# USB_USB2SS_PHY2_0F908000h register map
Vendor: Texas Instruments
Registers are 32-bit, read-write, reset 0x0 unless marked. A register's access mark holds for its fields unless they carry their own. Offsets are as the file gives them; [hi:lo] are bit positions; {n}, {i} and the like mark numbered series.

## usb2ss_phy2 (part 2 of 3)
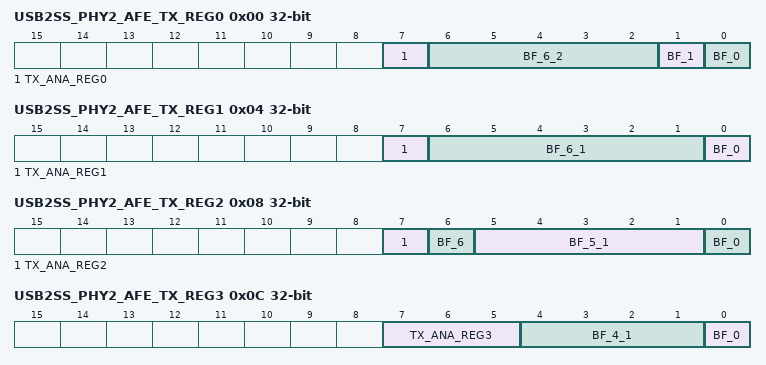
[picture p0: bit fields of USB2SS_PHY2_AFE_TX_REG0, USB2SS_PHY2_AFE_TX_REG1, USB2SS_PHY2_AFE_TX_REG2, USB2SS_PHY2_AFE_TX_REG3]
0x00 USB2SS_PHY2_AFE_TX_REG0 — This is a reserved register or field. It should not be written or read, and the value should be ignored.
  [7] TX_ANA_REG0 — This is a reserved register or field. It should not be written or read, and the value should be ignored. Reset Source: usb2_sync_preset_n
  [6:2] BF_6_2 — This is a reserved register or field. It should not be written or read, and the value should be ignored. Reset Source: usb2_sync_preset_n
  [1] BF_1 — This is a reserved register or field. It should not be written or read, and the value should be ignored. Reset Source: usb2_sync_preset_n
  [0] BF_0 — This is a reserved register or field. It should not be written or read, and the value should be ignored. Reset Source: usb2_sync_preset_n
0x04 USB2SS_PHY2_AFE_TX_REG1 — HS TX trimming
  [7] TX_ANA_REG1 — 0 SCALE1 VALUE IS 0, 1 SCALE1 VALUE IS 0.5 Reset Source: usb2_sync_preset_n
  [6:1] BF_6_1 — 000000 BOOST CODE VALUE IS 0, 000001 BOOST CODE VALUE IS 1, 000010 BOOST CODE VALUE IS 2, 00011 BOOST CODE VALUE IS 3, 000100 BOOST CODE VALUE IS 4, 000101 BOOST CODE VALUE IS 5, 000110 BOOST CODE VALUE IS 6, 000111 BOOST CODE VALUE IS 7, 001000 BOOST CODE VALUE IS 8, 001001 BOOST CODE VALUE IS 9, 001010 BOOST CODE VALUE IS 10, 001011 BOOST CODE VALUE IS 11, 001100 BOOST CODE VALUE IS 12, 001101 BOOST CODE VALUE IS 13, 001110 BOOST CODE VALUE IS 14, 001111 BOOST CODE VALUE IS 15, 010000 BOOST CODE VALUE IS 16, 010001 BOOST CODE VALUE IS 17, 010010 BOOST CODE VALUE IS 18, 010011 BOOST CODE VALUE IS 19, 010100 BOOST CODE VALUE IS 20, 010101 BOOST CODE VALUE IS 21, 010110 BOOST CODE VALUE IS 22, 010111 BOOST CODE VALUE IS 23, 011000 BOOST CODE VALUE IS 24, 011001 BOOST CODE VALUE IS 24, 011010 BOOST CODE VALUE IS 26, 011011 BOOST CODE VALUE IS 27, 011100 BOOST CODE VALUE IS 28, 011101 BOOST CODE VALUE IS 29, 011110 BOOST CODE VALUE IS 30, 011111 BOOST CODE VALUE IS 31, 100000 BOOST CODE VALUE IS 16, 100001 BOOST CODE VALUE IS 17, 100010 BOOST CODE VALUE IS 18, 100011 BOOST CODE VALUE IS 19, 100100 BOOST CODE VALUE IS 20, 100101 BOOST CODE VALUE IS 21, 100110 BOOST CODE VALUE IS 22, 100111 BOOST CODE VALUE IS 23, 101000 BOOST CODE VALUE IS 24 , 101001 BOOST CODE VALUE IS 24, 101010 BOOST CODE VALUE IS 26, 101011 BOOST CODE VALUE IS 27, 101100 BOOST CODE VALUE IS 28, 101101 BOOST CODE VALUE IS 29, 101110 BOOST CODE VALUE IS 30, 101111 BOOST CODE VALUE IS 31, 110000 BOOST CODE VALUE IS 32, 110001 BOOST CODE VALUE IS 33, 110010 BOOST CODE VALUE IS 34, 110011 BOOST CODE VALUE IS 35, 110100 BOOST CODE VALUE IS 36, 110101 BOOST CODE VALUE IS 37, 110110 BOOST CODE VALUE IS 38, 110111 BOOST CODE VALUE IS 39, 111000 BOOST CODE VALUE IS 40, 111001 BOOST CODE VALUE IS 41, 111010 BOOST CODE VALUE IS 42, 111011 BOOST CODE VALUE IS 43, 111100 BOOST CODE VALUE IS 44, 111101 BOOST CODE VALUE IS 45, 111110 BOOST CODE VALUE IS 46, 111111 BOOST CODE VALUE IS 47. Reset Source: usb2_sync_preset_n
  [0] BF_0 — 0 Default BOOST CODE = 8, 1 BOOST CODE can be controlled by BITS [6:1]. Reset Source: usb2_sync_preset_n
0x08 USB2SS_PHY2_AFE_TX_REG2 — HS TX trimming
  [7] TX_ANA_REG2 — This is a reserved register or field. It should not be written or read, and the value should be ignored. Reset Source: usb2_sync_preset_n
  [6] BF_6 — This is a reserved register or field. It should not be written or read, and the value should be ignored. Reset Source: usb2_sync_preset_n
  [5:1] BF_5_1 — 00000 DEEMP CODE VALUE IS 0, 00001 DEEMP CODE VALUE IS 1, 00010 DEEMP CODE VALUE IS 2, 00011 DEEMP CODE VALUE IS 3, 00100 DEEMP CODE VALUE IS 4, 00101 DEEMP CODE VALUE IS 5, 00110 DEEMP CODE VALUE IS 6, 00111 DEEMP CODE VALUE IS 7, 01000 DEEMP CODE VALUE IS 8, 01001 DEEMP CODE VALUE IS 9, 01010 DEEMP CODE VALUE IS 10, 01011 DEEMP CODE VALUE IS 11, 01100 DEEMP CODE VALUE IS 12, 01101 DEEMP CODE VALUE IS 13, 01110 DEEMP CODE VALUE IS 14, 01111 DEEMP CODE VALUE IS 15, 10000 DEEMP CODE VALUE IS 8, 10001 DEEMP CODE VALUE IS 9, 10010 DEEMP CODE VALUE IS 10, 10011 DEEMP CODE VALUE IS 11, 10100 DEEMP CODE VALUE IS 12, 10101 DEEMP CODE VALUE IS 13, 10110 DEEMP CODE VALUE IS 14, 10111 DEEMP CODE VALUE IS 15, 11000 DEEMP CODE VALUE IS 16, 11001 DEEMP CODE VALUE IS 17, 11010 DEEMP CODE VALUE IS 18, 11011 DEEMP CODE VALUE IS 19, 11100 DEEMP CODE VALUE IS 20, 11101 DEEMP CODE VALUE IS 21, 11110 DEEMP CODE VALUE IS 22, 11111 DEEMP CODE VALUE IS 23. Reset Source: usb2_sync_preset_n
  [0] BF_0 — 0 Default DEEMP CODE = 8, 1 DEEMP CODE can be controlled by BITS 5:1. Reset Source: usb2_sync_preset_n
0x0C USB2SS_PHY2_AFE_TX_REG3 — This is a reserved register or field. It should not be written or read, and the value should be ignored.
  [7:5] TX_ANA_REG3 — This is a reserved register or field. It should not be written or read, and the value should be ignored. Reset Source: usb2_sync_preset_n
  [4:1] BF_4_1 — This is a reserved register or field. It should not be written or read, and the value should be ignored. Reset Source: usb2_sync_preset_n
  [0] BF_0 — This is a reserved register or field. It should not be written or read, and the value should be ignored. Reset Source: usb2_sync_preset_n
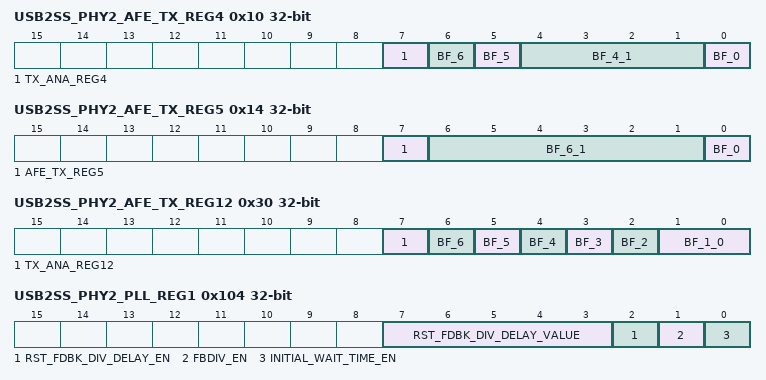
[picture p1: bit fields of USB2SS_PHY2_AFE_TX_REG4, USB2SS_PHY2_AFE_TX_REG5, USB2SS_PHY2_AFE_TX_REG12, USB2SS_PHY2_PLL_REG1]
0x10 USB2SS_PHY2_AFE_TX_REG4 — This is a reserved register or field. It should not be written or read, and the value should be ignored.
  [7] TX_ANA_REG4 — This is a reserved register or field. It should not be written or read, and the value should be ignored. Reset Source: usb2_sync_preset_n
  [6] BF_6 — This is a reserved register or field. It should not be written or read, and the value should be ignored. Reset Source: usb2_sync_preset_n
  [5] BF_5 — This is a reserved register or field. It should not be written or read, and the value should be ignored. Reset Source: usb2_sync_preset_n
  [4:1] BF_4_1 — This is a reserved register or field. It should not be written or read, and the value should be ignored. Reset Source: usb2_sync_preset_n
  [0] BF_0 — This is a reserved register or field. It should not be written or read, and the value should be ignored. Reset Source: usb2_sync_preset_n
0x14 USB2SS_PHY2_AFE_TX_REG5 — This is a reserved register or field. It should not be written or read, and the value should be ignored.
  [7] AFE_TX_REG5 — UNUSED Reset Source: usb2_sync_preset_n
  [6:1] BF_6_1 — This is a reserved register or field. It should not be written or read, and the value should be ignored. Reset Source: usb2_sync_preset_n
  [0] BF_0 — This is a reserved register or field. It should not be written or read, and the value should be ignored. Reset Source: usb2_sync_preset_n
0x18 USB2SS_PHY2_AFE_TX_REG6 — LSTX rise time trimming
  [7:0] TX_ANA_REG6 — Bit 7 = unused. Bbits 6:3= 0000 Typical LSTx rise time = 375ns, 0001 Typical LSTx rise time =215ns, 0010 Typical LSTx rise time =215ns, 0011 Typical LSTx rise time =150ns, 0100 Typical LSTx rise time =215ns, 0101 Typical LSTx rise time =150ns, 0110 Typical LSTx rise time =150ns, 0111 Typical LSTx rise time =115ns, 1000 Typical LSTx rise time =150ns, 1001 Typical LSTx rise time =115ns, 1010 Typical LSTx rise time =115ns, 1011 Typical LSTx rise time =94ns, 1100 Typical LSTx rise time =115ns, 1101 Typical LSTx rise time =94ns, 1110 Typical LSTx rise time =94ns, 1111 Typical LSTx rise time =79ns. Bit 6= 0 Typical LSTx rise time is set to default value of 150ns, 1 LSTX RISE TIME IS DETERMINED BY BITS 6:2. Bits 1:0 = reserved. Reset Source: usb2_sync_preset_n
0x1C USB2SS_PHY2_AFE_TX_REG7 — FSTX rise time trimming
  [7:0] TX_ANA_REG7 — Bits 7:5= reserved. Bits 4:1= 0000 Typical FSTx rise time = 16.6ns, 0001 Typical FSTx rise time =16.1ns, 0010 Typical FSTx rise time =15.6ns, 0011 Typical FSTx rise time =15.2ns, 0100 Typical FSTx rise time =14.7ns, 0101 Typical FSTx rise time =14.3ns, 0110 Typical FSTx rise time =13.9ns, 0111 Typical FSTx rise time =13.6ns, 1000 Typical FSTx rise time =13.2ns, 1001 Typical FSTx rise time =12.9ns, 1010 Typical FSTx rise time =12.6ns, 1011 Typical FSTx rise time =12.3ns, 1100 Typical FSTx rise time =12.0ns, 1101 Typical FSTx rise time =11.7ns, 1110 Typical FSTx rise time =11.5ns, 1111 Typical FSTx rise time =11.2ns. Bit 0= 0 FSTx rise time at typical corner is set to default value of 12ns, 1 FSTX RISE TIME IS DETERMINED BY BITS 4:1. Reset Source: usb2_sync_preset_n
0x20 USB2SS_PHY2_AFE_TX_REG8 — This is a reserved register or field. It should not be written or read, and the value should be ignored.
  [7:0] TX_ANA_REG8 — This is a reserved register or field. It should not be written or read, and the value should be ignored. Reset Source: usb2_sync_preset_n
0x24 USB2SS_PHY2_AFE_TX_REG9 — Register AFE_TX_REG9
  [7:0] TX_ANA_REG9 — Bits 7:4= 0000 Typical LSTx fall time = 450ns, 0001 Typical LSTx fall time = 225ns, 0010 Typical LSTx fall time =150ns, 0011 Typical LSTx fall time =225ns, 0100 Typical LSTx fall time =150ns, 0101 Typical LSTx fall time =150ns, 0110 Typical LSTx fall time =112ns, 0111 Typical LSTx fall time =150ns, 1000 Typical LSTx fall time =112ns, 1001 Typical LSTx fall time =112ns, 1010 Typical LSTx fall time =90ns, 1011 Typical LSTx fall time =112ns, 1100 Typical LSTx fall time =90ns, 1101 Typical LSTx fall time =90ns, 1110 Typical LSTx fall time =75ns, 1111 Typical LSTx fall time = 150ns. bit 3 = 0 LSTX FALL TIME IS DETERMINED BY DESIGN, 1 LSTX FALL TIME IS DETERMINED BY BITS 7:4. Bits 2:1= reserved. Reset Source: usb2_sync_preset_n
0x28 USB2SS_PHY2_AFE_TX_REG10 — FSTX fall time trimming
  [7:0] TX_ANA_REG10 — Bits 7:5= reserved. Bits 4:1= 0000 Typical FSTx fall time = 16.6ns, 0001 Typical FSTx fall time =16.1ns, 0010 Typical FSTx fall time =15.6ns, 0011 Typical FSTx fall time =15.2ns, 0100 Typical FSTx fall time =14.7ns, 0101 Typical FSTx fall time =14.3ns, 0110 Typical FSTx fall time =13.9ns, 0111 Typical FSTx fall time =13.6ns, 1000 Typical FSTx fall time =13.2ns, 1001 Typical FSTx fall time =12.9ns, 1010 Typical FSTx fall time =12.6ns, 1011 Typical FSTx fall time =12.3ns, 1100 Typical FSTx fall time =12ns, 1101 Typical FSTx fall time =11.7, 1110 Typical FSTx fall time =11.5ns, 1111 Typical FSTx fall time =11.2ns. bit 0 = 0 Typical FSTx fall time set to default value of 12ns, 1 FSTX fall TIME IS DETERMINED BY BITS 4:1. Reset Source: usb2_sync_preset_n
0x2C USB2SS_PHY2_AFE_TX_REG11 — This is a reserved register or field. It should not be written or read, and the value should be ignored.
  [7:0] TX_ANA_REG11 — This is a reserved register or field. It should not be written or read, and the value should be ignored. Reset Source: usb2_sync_preset_n
0x30 USB2SS_PHY2_AFE_TX_REG12 — Register AFE_TX_REG12
  [7] TX_ANA_REG12 — unused Reset Source: usb2_sync_preset_n
  [n] BF_{n} (n=2..6) — This is a reserved register or field. It should not be written or read, and the value should be ignored. Reset Source: usb2_sync_preset_n
  [1:0] BF_1_0 — 00- SCALE2 set to 0, 01- SCALE2 set to 1, 10- SCALE2 set to 1, 11- SCALE2 set to 2 Reset Source: usb2_sync_preset_n
0x34 USB2SS_PHY2_AFE_RX_REG0 — Trim the squelch threshold
  [7:0] RX_ANA_REG0 — Bits 7:6= reserved. Bits 5:0= 000000 keep squelch threshold at default value, 100000 increade squelch threshold by 5mv, 110000 increade squelch threshold by 10mv, 111000 increade squelch threshold by 15mv, 000001 reduce squelch threshold by 5mv, 000011 reduce squelch threshold by 10mv, 000111 reduce squelch threshold by 15mv. Reset Source: usb2_sync_preset_n
0x38 USB2SS_PHY2_AFE_RX_REG1 — This is a reserved register or field. It should not be written or read, and the value should be ignored.
  [7:0] RX_ANA_REG1 — This is a reserved register or field. It should not be written or read, and the value should be ignored. Reset Source: usb2_sync_preset_n
0x3C USB2SS_PHY2_AFE_RX_REG2 — This is a reserved register or field. It should not be written or read, and the value should be ignored.
  [7:0] RX_ANA_REG2 — reserved Reset Source: usb2_sync_preset_n
0x40 USB2SS_PHY2_AFE_RX_REG3 — This is a reserved register or field. It should not be written or read, and the value should be ignored.
  [7:0] RX_ANA_REG3 — This is a reserved register or field. It should not be written or read, and the value should be ignored. Reset Source: usb2_sync_preset_n
0x44 USB2SS_PHY2_AFE_RX_REG4 — This is a reserved register or field. It should not be written or read, and the value should be ignored.
  [7:0] RX_ANA_REG4 — This is a reserved register or field. It should not be written or read, and the value should be ignored. Reset Source: usb2_sync_preset_n
0x48 USB2SS_PHY2_AFE_RX_REG5 — Single ended receivers threshold trimming
  [7:0] RX_ANA_REG5 — Bits 7:3= reserved. Bits 2:1= 01 Switching thresholds for single ended receivers increased by 100mV, 10 Switching thresholds for single ended receivers reduced by 100mV. Bit 0= 0 Default Switching Thresholds for Single ended receivers, 1 SERx Switching Thresholds are controlled by bits [2:1]. Reset Source: usb2_sync_preset_n
0x4C USB2SS_PHY2_AFE_RX_REG6 — This is a reserved register or field. It should not be written or read, and the value should be ignored.
  [7:0] RX_ANA_REG6 — This is a reserved register or field. It should not be written or read, and the value should be ignored. Reset Source: usb2_sync_preset_n
0x50 USB2SS_PHY2_AFE_TX_REG13 ro — This is a reserved register or field. It should not be written or read, and the value should be ignored.
  [7:0] TX_ANA_REG13 — This is a reserved register or field. It should not be written or read, and the value should be ignored. Reset Source: usb2_sync_preset_n
0x54 USB2SS_PHY2_AFE_TX_REG14 ro — This is a reserved register or field. It should not be written or read, and the value should be ignored.
  [7:0] TX_ANA_REG14 — This is a reserved register or field. It should not be written or read, and the value should be ignored. Reset Source: usb2_sync_preset_n
0x58 USB2SS_PHY2_AFE_RX_REG7 ro — This is a reserved register or field. It should not be written or read, and the value should be ignored.
  [7:0] RX_ANA_REG7 — This is a reserved register or field. It should not be written or read, and the value should be ignored. Reset Source: usb2_sync_preset_n
0x5C USB2SS_PHY2_AFE_RX_REG8 ro — This is a reserved register or field. It should not be written or read, and the value should be ignored.
  [7:0] RX_ANA_REG8 — This is a reserved register or field. It should not be written or read, and the value should be ignored. Reset Source: usb2_sync_preset_n
0x60 USB2SS_PHY2_AFE_UNUSED_REG0 — AFE_UNUSED_REG0
  [7:0] AFE_UNUSED_REG0 — unused Reset Source: usb2_sync_preset_n
0x64 USB2SS_PHY2_AFE_UNUSED_REG1 — AFE_UNUSED_REG1
  [7:0] AFE_UNUSED_REG1 — unused Reset Source: usb2_sync_preset_n
0x80 USB2SS_PHY2_AFE_BG_REG0 — This is a reserved register or field. It should not be written or read, and the value should be ignored.
  [7:0] BG_ANA_REG0 — This is a reserved register or field. It should not be written or read, and the value should be ignored. Reset Source: usb2_sync_preset_n
0x84 USB2SS_PHY2_AFE_BG_REG1 — BG bias current trimming
  [7:0] BG_ANA_REG1 — Bits 7:6= 00- PLL charge pump bias current 5uA, 01- PLL charge pump bias current 4uA, 10- PLL charge pump bias current 6uA, 11- PLL charge pump bias current 5uA. Bits 5:4= 00- PLL DAC bias bias current bias current 5uA, 01- PLL DAC bias bias current bias current 4uA, 10- PLL DAC bias current current 6uA, 11- PLL DAC bias current current 5uA. Bits 3:2= 00- PLL DAC cascode bias current current 5uA, 01- PLL DAC cascode bias current current 4uA, 10- PLL DAC cascode bias current current 6uA, 11- PLL DAC cascode bias current current 5uA. Bits 1:0= 00- OTG block bias current 5uA, 01- OTG block bias current 6uA, 10- OTG block bias current 6uA, 11- OTG block bias current 5uA. Reset Source: usb2_sync_preset_n
0x88 USB2SS_PHY2_AFE_BG_REG2 — BG bias current trimming
  [7:0] BG_ANA_REG2 — Bits 7:5= 000 High speed receiver bias 5uA, 100 High speed receiver bias 1uA, 001 High speed receiver bias 4uA, 010 High speed receiver bias 6uA, 101 High speed receiver bias 2uA. Bits 4:2= 000 Trasmission Envelope Detector bias current 5uA, 100 Trasmission Envelope Detector bias current 1uA, 001 Trasmission Envelope Detector bias current 4uA, 101 Trasmission Envelope Detector bias current 6uA, 101 Trasmission Envelope Detector bias current 2uA. Bits 1:0=00 PLL LDO bias current 5uA, 01 PLL LDO bias current 6uA, 10 PLL LDO bias current 4uA, 11 PLL LDO bias current 5uA Reset Source: usb2_sync_preset_n
0x8C USB2SS_PHY2_AFE_BG_REG3 reset 0x2 — Register AFE_BG_REG3
  [7:0] BG_ANA_REG3 — Bits 7:6= reserved, Bits 5:4= 00 [Default] BG_OK_CORE Generated Internally, 01 BG_OK_CORE Generated Internally, 10 Force BG_OK_CORE =0, 11 Force BG_OK_CORE =1. Bits 3:0=0000 Invalid state, 0001 Higher start sense voltage, weaker start-up pull down, 0010 Default start sense voltage, 0100 Low start sense voltage, strong start-up pull down, 1000 Lowest start sense voltage, strongest start-up pull down. Reset Source: usb2_sync_preset_n
0x90 USB2SS_PHY2_AFE_CALIB_REG0 — Calibration resistance trimming
  [7:0] CALIB_ANA_REG0 — Bits 5:0= 000000 Calibrate termination resistor to default value, 000001 Calibrate termination resistor by -%5 to default value, 000011 Calibrate termination resistor by -%10 to default value, 000111 Calibrate termination resistor by - %15 to default value, 001000 Calibrate termination resistor by +5% to default value, 011000 Calibrate termination resistor by +10% to default value, 111000 Calibrate termination resistor by +15% to default value. Bits 7:6= reserved. Reset Source: usb2_sync_preset_n
0x94 USB2SS_PHY2_AFE_BC_REG0 — register AFE_BC_REG0
  [7:0] BC_ANA_REG0 — Bit 0= 0 Battery_charging_DAC_RES_CALIB CODE CANNOT BE CONTROLLED BY ANALOG TEST BITS, 1 Battery_charging_DAC_RES_CALIB CODE CAN BE CONTROLLED BY ANALOG TEST BITS. Bits 5:1= 00000 Battery_charging_DAC_RES_CALIB CODE FORCED TO 0, 00001 Battery_charging_DAC_RES_CALIB CODE FORCED TO 1, 00010 Battery_charging_DAC_RES_CALIB CODE FORCED TO 2, 00011 Battery_charging_DAC_RES_CALIB CODE FORCED TO 3, 00100 Battery_charging_DAC_RES_CALIB CODE FORCED TO 4, 00101 Battery_charging_DAC_RES_CALIB CODE FORCED TO 5, 00110 Battery_charging_DAC_RES_CALIB CODE FORCED TO 6, 00111 Battery_charging_DAC_RES_CALIB CODE FORCED TO 7, 01000 Battery_charging_DAC_RES_CALIB CODE FORCED TO 8, 01001 Battery_charging_DAC_RES_CALIB CODE FORCED TO 9, 01010 Battery_charging_DAC_RES_CALIB CODE FORCED TO 10, 01011 Battery_charging_DAC_RES_CALIB CODE FORCED TO 11, 01100 Battery_charging_DAC_RES_CALIB CODE FORCED TO 12, 01101 Battery_charging_DAC_RES_CALIB CODE FORCED TO 13, 01110 Battery_charging_DAC_RES_CALIB CODE FORCED TO 14, 01111 Battery_charging_DAC_RES_CALIB CODE FORCED TO 15, 10000 Battery_charging_DAC_RES_CALIB CODE FORCED TO 16, 10001 Battery_charging_DAC_RES_CALIB CODE FORCED TO 17, 10010 Battery_charging_DAC_RES_CALIB CODE FORCED TO 18, 10011 Battery_charging_DAC_RES_CALIB CODE FORCED TO 19, 10100 Battery_charging_DAC_RES_CALIB CODE FORCED TO 20, 10101 Battery_charging_DAC_RES_CALIB CODE FORCED TO 21, 10110 Battery_charging_DAC_RES_CALIB CODE FORCED TO 22, 10111 Battery_charging_DAC_RES_CALIB CODE FORCED TO 23, 11000 Battery_charging_DAC_RES_CALIB CODE FORCED TO 24, 11001 Battery_charging_DAC_RES_CALIB CODE FORCED TO 24, 11010 Battery_charging_DAC_RES_CALIB CODE FORCED TO 26, 11011 Battery_charging_DAC_RES_CALIB CODE FORCED TO 27, 11100 Battery_charging_DAC_RES_CALIB CODE FORCED TO 28, 11101 Battery_charging_DAC_RES_CALIB CODE FORCED TO 29, 11110 Battery_charging_DAC_RES_CALIB CODE FORCED TO 30, 11111 Battery_charging_DAC_RES_CALIB CODE FORCED TO 31. Bits 7:6= reserved. Reset Source: usb2_sync_preset_n
0x98 USB2SS_PHY2_AFE_BC_REG1 — This is a reserved register or field. It should not be written or read, and the value should be ignored.
  [7:0] BC_ANA_REG1 — This is a reserved register or field. It should not be written or read, and the value should be ignored. Reset Source: usb2_sync_preset_n
0x9C USB2SS_PHY2_AFE_BC_REG2 — This is a reserved register or field. It should not be written or read, and the value should be ignored.
  [7:0] BC_ANA_REG2 — This is a reserved register or field. It should not be written or read, and the value should be ignored. Reset Source: usb2_sync_preset_n
0xA0 USB2SS_PHY2_AFE_BC_REG3 — Register AFE_BC_REG3
  [7:0] BC_ANA_REG3 — Bit 0= 0 Do not overdrive SESS_VLD comparator enable signal, 1 Overdrive SESS_VLD comparator enable signal. Bit 1= 0 SESS_VLD comparator disabled, 1 SESS_VLD comparator enabled. Bit 2= 0 Do not overdrive VBUS_VLD comparator enable signal, 1 Overdrive VBUS_VLD comparator enable signal. Bit 3= 0 VBUS_VLD comparator disabled, 1 VBUS_VLD comparator enabled. Bit 4= 0 Do not overdrive ID comparator enable signal, 1 Overdrive ID comparator enable signal. Bit 5= 0 ID comparator disabled, 1 ID comparator enabled. Bits 7:6= reserved. Reset Source: usb2_sync_preset_n
0xA4 USB2SS_PHY2_AFE_BC_REG4 — Register AFE_BC_REG4
  [7:0] BC_ANA_REG4 — Bits 2:0= reserved. Bit 3= 0- VBUS_VLD comparator output low, 1- VBUS_VLD comparator output high. Bit 4= 0- Do not overdrive VBUS_VLD comparator output, 1- Overdrive VBUS_VLD comparator output. Bit 5= 0- SESS_VLD comparator output low, 1- SESS_VLD comparator output high. Bit 6= 0- Do not overdrive SESS_VLD comparator output, 1- Overdrive SESS_VLD comparator output. Bit 7= 0- ID comparator output low, 1- ID comparator output high. Reset Source: usb2_sync_preset_n
0xA8 USB2SS_PHY2_AFE_BC_REG5 — Register AFE_BC_REG5
  [7:0] BC_ANA_REG5 — Bit 0= 0- Do not overdrive ID comparator output, 1- Overdrive ID comparator output. Bit 1= 0 Do not overdrive VBUS_DIV signal, 1- Overdrive VBUS_DIV signal. Bit 2= 0- VBUS_DIV signal low, 1- VBUS_DIV signal high. Bits 7:3= reserved. Reset Source: usb2_sync_preset_n
0xAC USB2SS_PHY2_AFE_BC_REG6 — Register AFE_BC_REG6
  [7:0] BC_ANA_REG6 — register AFE_BC_REG6 Reset Source: usb2_sync_preset_n
{0xB0+4i} USB2SS_PHY2_AFE_PLL_REG{i} (i=0..5) — This is a reserved register or field. It should not be written or read, and the value should be ignored.
  [7:0] AFE_PLL_REG{i} — This is a reserved register or field. It should not be written or read, and the value should be ignored. Reset Source: usb2_sync_preset_n
0xC8 USB2SS_PHY2_AFE_BG_REG4 ro — This is a reserved register or field. It should not be written or read, and the value should be ignored.
  [7:0] BG_ANA_REG4 — This is a reserved register or field. It should not be written or read, and the value should be ignored. Reset Source: usb2_sync_preset_n
0xCC USB2SS_PHY2_AFE_CALIB_REG1 ro — This is a reserved register or field. It should not be written or read, and the value should be ignored.
  [7:0] CALIB_ANA_REG1 — This is a reserved register or field. It should not be written or read, and the value should be ignored. Reset Source: usb2_sync_preset_n
0xD0 USB2SS_PHY2_AFE_BC_REG7 ro — This is a reserved register or field. It should not be written or read, and the value should be ignored.
  [7:0] BC_ANA_REG7 — This is a reserved register or field. It should not be written or read, and the value should be ignored. Reset Source: usb2_sync_preset_n
0xD4 USB2SS_PHY2_AFE_PLL_REG6 ro — This is a reserved register or field. It should not be written or read, and the value should be ignored.
  [7:0] PLL_ANA_REG6 — This is a reserved register or field. It should not be written or read, and the value should be ignored. Reset Source: usb2_sync_preset_n
0xD8 USB2SS_PHY2_AFE_UNUSED_REG2 (reset mask 0xFF) — This is a reserved register or field. It should not be written or read, and the value should be ignored.
0xDC USB2SS_PHY2_AFE_UNUSED_REG3 (reset mask 0xFF) — AFE_UNUSED_REG3
0x100 USB2SS_PHY2_PLL_REG0 — This is a reserved register or field. It should not be written or read, and the value should be ignored.
  [7:0] INITIAL_WAIT_TIME — This is a reserved register or field. It should not be written or read, and the value should be ignored. Reset Source: usb2_sync_preset_n
0x104 USB2SS_PHY2_PLL_REG1 — This is a reserved register or field. It should not be written or read, and the value should be ignored.
  [7:3] RST_FDBK_DIV_DELAY_VALUE — This is a reserved register or field. It should not be written or read, and the value should be ignored. Reset Source: usb2_sync_preset_n
  [2] RST_FDBK_DIV_DELAY_EN — This is a reserved register or field. It should not be written or read, and the value should be ignored. Reset Source: usb2_sync_preset_n
  [1] FBDIV_EN — This is a reserved register or field. It should not be written or read, and the value should be ignored. Reset Source: usb2_sync_preset_n
  [0] INITIAL_WAIT_TIME_EN — This is a reserved register or field. It should not be written or read, and the value should be ignored. Reset Source: usb2_sync_preset_n
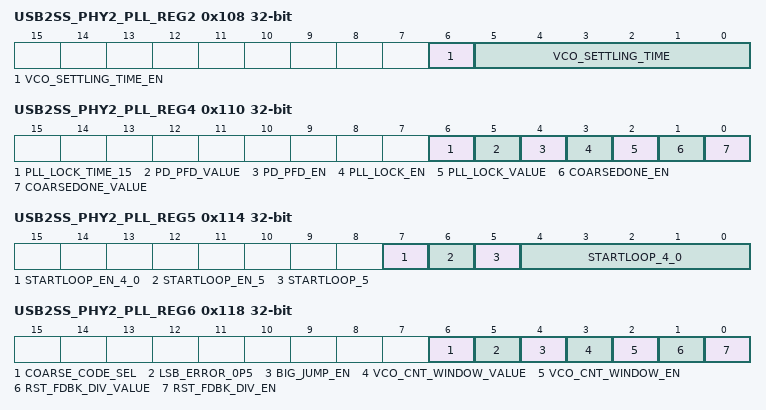
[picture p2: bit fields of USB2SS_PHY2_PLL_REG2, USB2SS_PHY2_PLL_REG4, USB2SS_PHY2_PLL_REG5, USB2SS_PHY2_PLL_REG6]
0x108 USB2SS_PHY2_PLL_REG2 — This is a reserved register or field. It should not be written or read, and the value should be ignored.
  [6] VCO_SETTLING_TIME_EN — This is a reserved register or field. It should not be written or read, and the value should be ignored. Reset Source: usb2_sync_preset_n
  [5:0] VCO_SETTLING_TIME — This is a reserved register or field. It should not be written or read, and the value should be ignored. Reset Source: usb2_sync_preset_n
0x10C USB2SS_PHY2_PLL_REG3 — This is a reserved register or field. It should not be written or read, and the value should be ignored.
  [7:0] FBDIV_VALUE — This is a reserved register or field. It should not be written or read, and the value should be ignored. Reset Source: usb2_sync_preset_n
0x110 USB2SS_PHY2_PLL_REG4 — This is a reserved register or field. It should not be written or read, and the value should be ignored.
  [6] PLL_LOCK_TIME_15 — This is a reserved register or field. It should not be written or read, and the value should be ignored. Reset Source: usb2_sync_preset_n
  [5] PD_PFD_VALUE — This is a reserved register or field. It should not be written or read, and the value should be ignored. Reset Source: usb2_sync_preset_n
  [4] PD_PFD_EN — This is a reserved register or field. It should not be written or read, and the value should be ignored. Reset Source: usb2_sync_preset_n
  [3] PLL_LOCK_EN — This is a reserved register or field. It should not be written or read, and the value should be ignored. Reset Source: usb2_sync_preset_n
  [2] PLL_LOCK_VALUE — This is a reserved register or field. It should not be written or read, and the value should be ignored. Reset Source: usb2_sync_preset_n
  [1] COARSEDONE_EN — This is a reserved register or field. It should not be written or read, and the value should be ignored. Reset Source: usb2_sync_preset_n
  [0] COARSEDONE_VALUE — This is a reserved register or field. It should not be written or read, and the value should be ignored. Reset Source: usb2_sync_preset_n
0x114 USB2SS_PHY2_PLL_REG5 — This is a reserved register or field. It should not be written or read, and the value should be ignored.
  [7] STARTLOOP_EN_4_0 — This is a reserved register or field. It should not be written or read, and the value should be ignored. Reset Source: usb2_sync_preset_n
  [6] STARTLOOP_EN_5 — This is a reserved register or field. It should not be written or read, and the value should be ignored. Reset Source: usb2_sync_preset_n
  [5] STARTLOOP_5 — This is a reserved register or field. It should not be written or read, and the value should be ignored. Reset Source: usb2_sync_preset_n
  [4:0] STARTLOOP_4_0 — This is a reserved register or field. It should not be written or read, and the value should be ignored. Reset Source: usb2_sync_preset_n
0x118 USB2SS_PHY2_PLL_REG6 — This is a reserved register or field. It should not be written or read, and the value should be ignored.
  [6] COARSE_CODE_SEL — This is a reserved register or field. It should not be written or read, and the value should be ignored. Reset Source: usb2_sync_preset_n
  [5] LSB_ERROR_0P5 — This is a reserved register or field. It should not be written or read, and the value should be ignored. Reset Source: usb2_sync_preset_n
  [4] BIG_JUMP_EN — This is a reserved register or field. It should not be written or read, and the value should be ignored. Reset Source: usb2_sync_preset_n
  [3] VCO_CNT_WINDOW_VALUE — This is a reserved register or field. It should not be written or read, and the value should be ignored. Reset Source: usb2_sync_preset_n
  [2] VCO_CNT_WINDOW_EN — This is a reserved register or field. It should not be written or read, and the value should be ignored. Reset Source: usb2_sync_preset_n
  [1] RST_FDBK_DIV_VALUE — This is a reserved register or field. It should not be written or read, and the value should be ignored. Reset Source: usb2_sync_preset_n
  [0] RST_FDBK_DIV_EN — This is a reserved register or field. It should not be written or read, and the value should be ignored. Reset Source: usb2_sync_preset_n
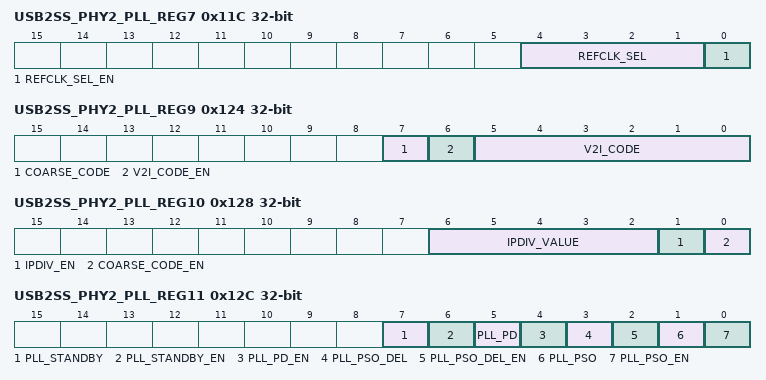
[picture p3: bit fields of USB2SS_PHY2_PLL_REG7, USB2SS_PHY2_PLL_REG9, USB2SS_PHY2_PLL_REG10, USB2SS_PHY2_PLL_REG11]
0x11C USB2SS_PHY2_PLL_REG7 — refclock selection
  [4:1] REFCLK_SEL — 0000 Refclock selection for 9.6 MHz, 0001 Refclock selection for 10 MHz, 0010 Refclock selection for 12 MHz, 0011 Refclock selection for 19.2 MHz, 0100 Refclock selection for 20 MHz, 0101 Refclock selection for 24 MHz, 0110 Refclock selection for 25 MHz, 0111 Refclock selection for 26 MHz, 1000 Refclock selection for 38.4 MHz, 1001 Refclock selection for 40 MHz, 1010 Refclock selection for 48 MHz, 1011 Refclock selection for 50 MHz, 1100 Refclock selection for 52 MHz, 1101 Refclock selection for 9.6 MHz, 1110 Refclock selection for 9.6 MHz, 1111 Refclock selection for 9.6 MHz. Reset Source: usb2_sync_preset_n
  [0] REFCLK_SEL_EN — 0 PLLREFSEL Value not taken from PLL_REG7[4:1], 1 PLLREFSEL Value taken from PLL_REG7[4:1]. Reset Source: usb2_sync_preset_n
0x120 USB2SS_PHY2_PLL_REG8 — This is a reserved register or field. It should not be written or read, and the value should be ignored.
  [7:0] COARSE_CODE — This is a reserved register or field. It should not be written or read, and the value should be ignored. Reset Source: usb2_sync_preset_n
0x124 USB2SS_PHY2_PLL_REG9 — This is a reserved register or field. It should not be written or read, and the value should be ignored.
  [7] COARSE_CODE — This is a reserved register or field. It should not be written or read, and the value should be ignored. Reset Source: usb2_sync_preset_n
  [6] V2I_CODE_EN — This is a reserved register or field. It should not be written or read, and the value should be ignored. Reset Source: usb2_sync_preset_n
  [5:0] V2I_CODE — This is a reserved register or field. It should not be written or read, and the value should be ignored. Reset Source: usb2_sync_preset_n
0x128 USB2SS_PHY2_PLL_REG10 — This is a reserved register or field. It should not be written or read, and the value should be ignored.
  [6:2] IPDIV_VALUE — This is a reserved register or field. It should not be written or read, and the value should be ignored. Reset Source: usb2_sync_preset_n
  [1] IPDIV_EN — This is a reserved register or field. It should not be written or read, and the value should be ignored. Reset Source: usb2_sync_preset_n
  [0] COARSE_CODE_EN — This is a reserved register or field. It should not be written or read, and the value should be ignored. Reset Source: usb2_sync_preset_n
0x12C USB2SS_PHY2_PLL_REG11 — This is a reserved register or field. It should not be written or read, and the value should be ignored.
  [7] PLL_STANDBY — This is a reserved register or field. It should not be written or read, and the value should be ignored. Reset Source: usb2_sync_preset_n
  [6] PLL_STANDBY_EN — This is a reserved register or field. It should not be written or read, and the value should be ignored. Reset Source: usb2_sync_preset_n
  [5] PLL_PD — This is a reserved register or field. It should not be written or read, and the value should be ignored. Reset Source: usb2_sync_preset_n
  [4] PLL_PD_EN — This is a reserved register or field. It should not be written or read, and the value should be ignored. Reset Source: usb2_sync_preset_n
  [3] PLL_PSO_DEL — This is a reserved register or field. It should not be written or read, and the value should be ignored. Reset Source: usb2_sync_preset_n
  [2] PLL_PSO_DEL_EN — This is a reserved register or field. It should not be written or read, and the value should be ignored. Reset Source: usb2_sync_preset_n
  [1] PLL_PSO — This is a reserved register or field. It should not be written or read, and the value should be ignored. Reset Source: usb2_sync_preset_n
  [0] PLL_PSO_EN — This is a reserved register or field. It should not be written or read, and the value should be ignored. Reset Source: usb2_sync_preset_n
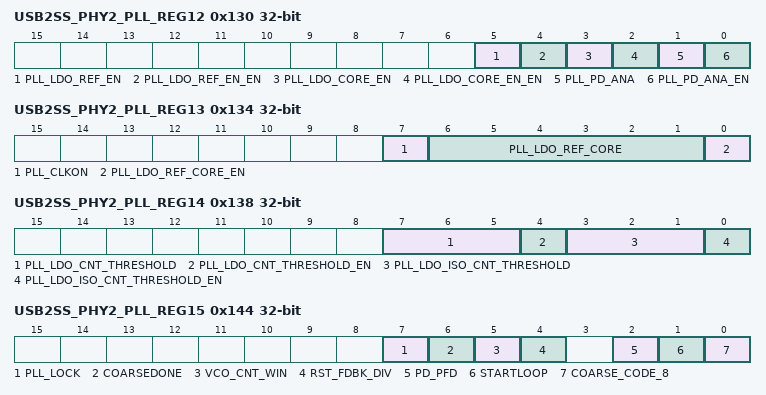
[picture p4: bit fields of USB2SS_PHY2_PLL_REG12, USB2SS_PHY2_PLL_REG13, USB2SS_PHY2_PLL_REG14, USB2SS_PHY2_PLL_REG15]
0x130 USB2SS_PHY2_PLL_REG12 — This is a reserved register or field. It should not be written or read, and the value should be ignored.
  [5] PLL_LDO_REF_EN — This is a reserved register or field. It should not be written or read, and the value should be ignored. Reset Source: usb2_sync_preset_n
  [4] PLL_LDO_REF_EN_EN — This is a reserved register or field. It should not be written or read, and the value should be ignored. Reset Source: usb2_sync_preset_n
  [3] PLL_LDO_CORE_EN — This is a reserved register or field. It should not be written or read, and the value should be ignored. Reset Source: usb2_sync_preset_n
  [2] PLL_LDO_CORE_EN_EN — This is a reserved register or field. It should not be written or read, and the value should be ignored. Reset Source: usb2_sync_preset_n
  [1] PLL_PD_ANA — This is a reserved register or field. It should not be written or read, and the value should be ignored. Reset Source: usb2_sync_preset_n
  [0] PLL_PD_ANA_EN — This is a reserved register or field. It should not be written or read, and the value should be ignored. Reset Source: usb2_sync_preset_n
0x134 USB2SS_PHY2_PLL_REG13 — PLL clockon test mode
  [7] PLL_CLKON — 0 pll clock is not always running, 1 pll clock is always running. Reset Source: usb2_sync_preset_n
  [6:1] PLL_LDO_REF_CORE — This is a reserved register or field. It should not be written or read, and the value should be ignored. Reset Source: usb2_sync_preset_n
  [0] PLL_LDO_REF_CORE_EN — This is a reserved register or field. It should not be written or read, and the value should be ignored. Reset Source: usb2_sync_preset_n
0x138 USB2SS_PHY2_PLL_REG14 — This is a reserved register or field. It should not be written or read, and the value should be ignored.
  [7:5] PLL_LDO_CNT_THRESHOLD — This is a reserved register or field. It should not be written or read, and the value should be ignored. Reset Source: usb2_sync_preset_n
  [4] PLL_LDO_CNT_THRESHOLD_EN — This is a reserved register or field. It should not be written or read, and the value should be ignored. Reset Source: usb2_sync_preset_n
  [3:1] PLL_LDO_ISO_CNT_THRESHOLD — This is a reserved register or field. It should not be written or read, and the value should be ignored. Reset Source: usb2_sync_preset_n
  [0] PLL_LDO_ISO_CNT_THRESHOLD_EN — This is a reserved register or field. It should not be written or read, and the value should be ignored. Reset Source: usb2_sync_preset_n
0x13C USB2SS_PHY2_PLL_UNUSED_REG0 (reset mask 0xFF) — unused
0x140 USB2SS_PHY2_PLL_UNUSED_REG1 (reset mask 0xFF) — unused
0x144 USB2SS_PHY2_PLL_REG15 ro — Coarse_code values
  [7] PLL_LOCK — This is a reserved register or field. It should not be written or read, and the value should be ignored. Reset Source: usb2_sync_preset_n
  [6] COARSEDONE — This is a reserved register or field. It should not be written or read, and the value should be ignored. Reset Source: usb2_sync_preset_n
  [5] VCO_CNT_WIN — This is a reserved register or field. It should not be written or read, and the value should be ignored. Reset Source: usb2_sync_preset_n
  [4] RST_FDBK_DIV — This is a reserved register or field. It should not be written or read, and the value should be ignored. Reset Source: usb2_sync_preset_n
  [2] PD_PFD — This is a reserved register or field. It should not be written or read, and the value should be ignored. Reset Source: usb2_sync_preset_n
  [1] STARTLOOP — This is a reserved register or field. It should not be written or read, and the value should be ignored. Reset Source: usb2_sync_preset_n
  [0] COARSE_CODE_8 — 0 MSB of coarse_code for PLL VCO. Reset Source: usb2_sync_preset_n
0x148 USB2SS_PHY2_PLL_REG16 ro — Coarse_code values
  [7:0] COARSE_CODE — 01011010 8 LSBs of coarse code for PLL VCO Reset Source: usb2_sync_preset_n
0x14C USB2SS_PHY2_PLL_UNUSED_REG2 ro (reset mask 0xFF) — unused
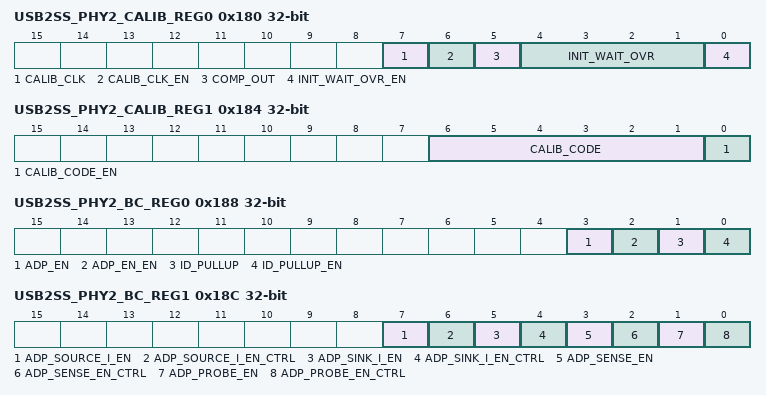
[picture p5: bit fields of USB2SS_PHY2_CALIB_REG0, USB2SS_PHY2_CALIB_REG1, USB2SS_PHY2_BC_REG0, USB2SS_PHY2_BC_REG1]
0x180 USB2SS_PHY2_CALIB_REG0 — This is a reserved register or field. It should not be written or read, and the value should be ignored.
  [7] CALIB_CLK — This is a reserved register or field. It should not be written or read, and the value should be ignored. Reset Source: usb2_sync_preset_n
  [6] CALIB_CLK_EN — This is a reserved register or field. It should not be written or read, and the value should be ignored. Reset Source: usb2_sync_preset_n
  [5] COMP_OUT — This is a reserved register or field. It should not be written or read, and the value should be ignored. Reset Source: usb2_sync_preset_n
  [4:1] INIT_WAIT_OVR — This is a reserved register or field. It should not be written or read, and the value should be ignored. Reset Source: usb2_sync_preset_n
  [0] INIT_WAIT_OVR_EN — This is a reserved register or field. It should not be written or read, and the value should be ignored. Reset Source: usb2_sync_preset_n
0x184 USB2SS_PHY2_CALIB_REG1 — This is a reserved register or field. It should not be written or read, and the value should be ignored.
  [6:1] CALIB_CODE — This is a reserved register or field. It should not be written or read, and the value should be ignored. Reset Source: usb2_sync_preset_n
  [0] CALIB_CODE_EN — This is a reserved register or field. It should not be written or read, and the value should be ignored. Reset Source: usb2_sync_preset_n
0x188 USB2SS_PHY2_BC_REG0 — This is a reserved register or field. It should not be written or read, and the value should be ignored.
  [3] ADP_EN — This is a reserved register or field. It should not be written or read, and the value should be ignored. Reset Source: usb2_sync_preset_n
  [2] ADP_EN_EN — This is a reserved register or field. It should not be written or read, and the value should be ignored. Reset Source: usb2_sync_preset_n
  [1] ID_PULLUP — This is a reserved register or field. It should not be written or read, and the value should be ignored. Reset Source: usb2_sync_preset_n
  [0] ID_PULLUP_EN — This is a reserved register or field. It should not be written or read, and the value should be ignored. Reset Source: usb2_sync_preset_n
0x18C USB2SS_PHY2_BC_REG1 — This is a reserved register or field. It should not be written or read, and the value should be ignored.
  [7] ADP_SOURCE_I_EN — This is a reserved register or field. It should not be written or read, and the value should be ignored. Reset Source: usb2_sync_preset_n
  [6] ADP_SOURCE_I_EN_CTRL — This is a reserved register or field. It should not be written or read, and the value should be ignored. Reset Source: usb2_sync_preset_n
  [5] ADP_SINK_I_EN — This is a reserved register or field. It should not be written or read, and the value should be ignored. Reset Source: usb2_sync_preset_n
  [4] ADP_SINK_I_EN_CTRL — This is a reserved register or field. It should not be written or read, and the value should be ignored. Reset Source: usb2_sync_preset_n
  [3] ADP_SENSE_EN — This is a reserved register or field. It should not be written or read, and the value should be ignored. Reset Source: usb2_sync_preset_n
  [2] ADP_SENSE_EN_CTRL — This is a reserved register or field. It should not be written or read, and the value should be ignored. Reset Source: usb2_sync_preset_n
  [1] ADP_PROBE_EN — This is a reserved register or field. It should not be written or read, and the value should be ignored. Reset Source: usb2_sync_preset_n
  [0] ADP_PROBE_EN_CTRL — This is a reserved register or field. It should not be written or read, and the value should be ignored. Reset Source: usb2_sync_preset_n
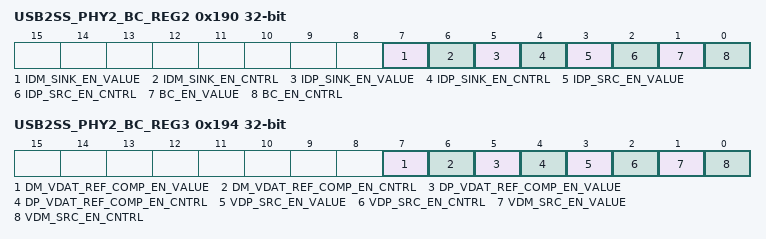
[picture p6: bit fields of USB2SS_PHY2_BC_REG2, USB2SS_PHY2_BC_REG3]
0x190 USB2SS_PHY2_BC_REG2 — This is a reserved register or field. It should not be written or read, and the value should be ignored.
  [7] IDM_SINK_EN_VALUE — This is a reserved register or field. It should not be written or read, and the value should be ignored. Reset Source: usb2_sync_preset_n
  [6] IDM_SINK_EN_CNTRL — This is a reserved register or field. It should not be written or read, and the value should be ignored. Reset Source: usb2_sync_preset_n
  [5] IDP_SINK_EN_VALUE — This is a reserved register or field. It should not be written or read, and the value should be ignored. Reset Source: usb2_sync_preset_n
  [4] IDP_SINK_EN_CNTRL — This is a reserved register or field. It should not be written or read, and the value should be ignored. Reset Source: usb2_sync_preset_n
  [3] IDP_SRC_EN_VALUE — This is a reserved register or field. It should not be written or read, and the value should be ignored. Reset Source: usb2_sync_preset_n
  [2] IDP_SRC_EN_CNTRL — This is a reserved register or field. It should not be written or read, and the value should be ignored. Reset Source: usb2_sync_preset_n
  [1] BC_EN_VALUE — This is a reserved register or field. It should not be written or read, and the value should be ignored. Reset Source: usb2_sync_preset_n
  [0] BC_EN_CNTRL — This is a reserved register or field. It should not be written or read, and the value should be ignored. Reset Source: usb2_sync_preset_n
0x194 USB2SS_PHY2_BC_REG3 — This is a reserved register or field. It should not be written or read, and the value should be ignored.
  [7] DM_VDAT_REF_COMP_EN_VALUE — This is a reserved register or field. It should not be written or read, and the value should be ignored. Reset Source: usb2_sync_preset_n
  [6] DM_VDAT_REF_COMP_EN_CNTRL — This is a reserved register or field. It should not be written or read, and the value should be ignored. Reset Source: usb2_sync_preset_n
  [5] DP_VDAT_REF_COMP_EN_VALUE — This is a reserved register or field. It should not be written or read, and the value should be ignored. Reset Source: usb2_sync_preset_n
  [4] DP_VDAT_REF_COMP_EN_CNTRL — This is a reserved register or field. It should not be written or read, and the value should be ignored. Reset Source: usb2_sync_preset_n
  [3] VDP_SRC_EN_VALUE — This is a reserved register or field. It should not be written or read, and the value should be ignored. Reset Source: usb2_sync_preset_n
  [2] VDP_SRC_EN_CNTRL — This is a reserved register or field. It should not be written or read, and the value should be ignored. Reset Source: usb2_sync_preset_n
  [1] VDM_SRC_EN_VALUE — This is a reserved register or field. It should not be written or read, and the value should be ignored. Reset Source: usb2_sync_preset_n
  [0] VDM_SRC_EN_CNTRL — This is a reserved register or field. It should not be written or read, and the value should be ignored. Reset Source: usb2_sync_preset_n
